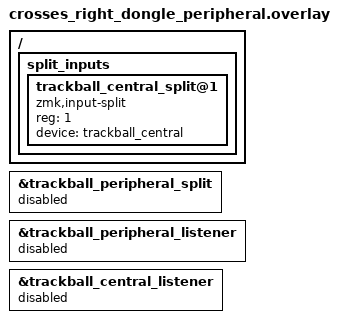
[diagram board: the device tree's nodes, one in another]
&trackball_peripheral_split {
    status = "disabled";
};

/ {
    split_inputs {
        #address-cells = <1>;
        #size-cells = <0>;

        trackball_central_split@1 {
            compatible = "zmk,input-split";
            reg = <1>;
            device = <&trackball_central>;
        };
    };
};

&trackball_peripheral_listener {
    status = "disabled";
};

&trackball_central_listener {
    status = "disabled";
};
